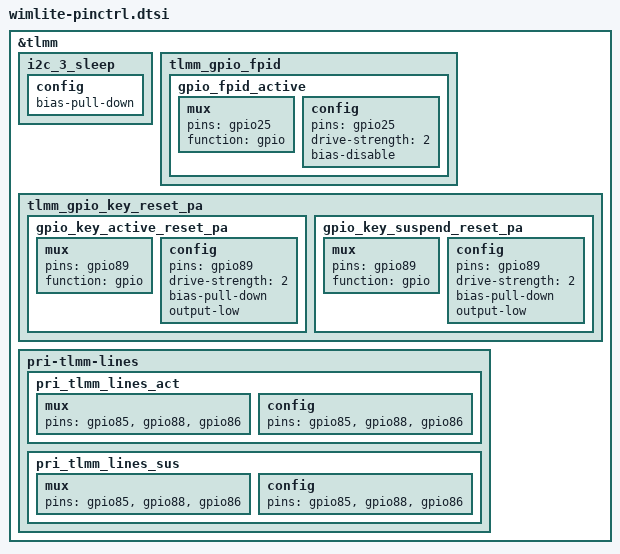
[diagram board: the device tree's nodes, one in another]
/*
 * Copyright (c) 2015-2016, The Linux Foundation. All rights reserved.
 *
 * This program is free software; you can redistribute it and/or modify
 * it under the terms of the GNU General Public License version 2 and
 * only version 2 as published by the Free Software Foundation.
 *
 * This program is distributed in the hope that it will be useful,
 * but WITHOUT ANY WARRANTY; without even the implied warranty of
 * MERCHANTABILITY or FITNESS FOR A PARTICULAR PURPOSE.  See the
 * GNU General Public License for more details.
 */
&tlmm {

	i2c_3_sleep {
		config {
			bias-pull-down;
		};
	};

	tlmm_gpio_fpid {
		gpio_fpid_active: gpio_fpid_active {
			mux {
				pins = "gpio25";
				function = "gpio";
			};
			config {
				pins = "gpio25";
				drive-strength = <2>;
				bias-disable;
			};
		};
	};

	tlmm_gpio_key_reset_pa {
		gpio_key_active_reset_pa: gpio_key_active_reset_pa {
			mux {
				pins = "gpio89";
				function = "gpio";
			};
			config {
				pins = "gpio89";
				drive-strength = <2>;
				bias-pull-down;
				output-low;
			};
		};
		gpio_key_suspend_reset_pa: gpio_key_suspend_reset_pa {
			mux {
				pins = "gpio89";
				function = "gpio";
			};
			config {
				pins = "gpio89";
				drive-strength = <2>;
				bias-pull-down;
				output-low;
			};
		};
	};

	pri-tlmm-lines {
		pri_tlmm_lines_act {
			mux {
				pins = "gpio85", "gpio88","gpio86";
			};
			config {
				pins = "gpio85", "gpio88","gpio86";
			};
		};
		pri_tlmm_lines_sus {
			mux {
				pins = "gpio85", "gpio88","gpio86";
			};
			config {
				pins = "gpio85", "gpio88","gpio86";
			};
		};
	};
};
